# ET6801 register map
Vendor: ETMCU Inc.; File version: v0.0.1
CPU: CM7 r2p1, little endian, MPU, FPU, I-cache, D-cache, ITCM, DTCM, 4 interrupt priority bits
Registers are 32-bit, read-write, reset 0x0 unless marked. A register's access mark holds for its fields unless they carry their own. Offsets are from the block's base; [hi:lo] are bit positions.

## SRAMCTL0 — Provide an overview of the purpose and functionality of the peripheral: axi2sram
Base 0x40608000
Same registers: SRAMCTL1 0x40609000
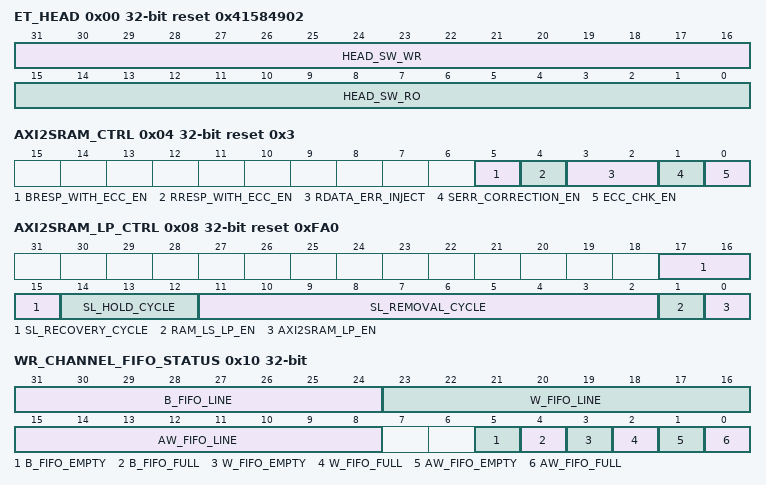
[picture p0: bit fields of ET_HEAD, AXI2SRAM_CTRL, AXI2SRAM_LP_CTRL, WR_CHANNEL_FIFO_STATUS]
0x00 ET_HEAD reset 0x41584902
  [31:16] HEAD_SW_WR — 软件测试读写寄存器，硬件无访问
  [15:0] HEAD_SW_RO ro — 软件只读上报寄存器，硬件无访问
0x04 AXI2SRAM_CTRL reset 0x3
  [5] BRESP_WITH_ECC_EN — AXI2SRAM bresp ecc使能
  [4] RRESP_WITH_ECC_EN — AXI2SRAM rresp ecc使能
  [3:2] RDATA_ERR_INJECT — AXI2SRAM ECC注错使能
  [1] SERR_CORRECTION_EN — AXI2SRAM ECC单bit错误纠错使能
  [0] ECC_CHK_EN — AXI2SRAM ECC使能
0x08 AXI2SRAM_LP_CTRL reset 0xFA0
  [17:15] SL_RECOVERY_CYCLE — MEM_RAM Light-sleep recovery时间配置，默认为0
  [14:12] SL_HOLD_CYCLE — MEM_RAM Light-sleep hold时间配置，默认为0
  [11:2] SL_REMOVAL_CYCLE — MEM_RAM Light-sleep removal时间配置，默认为1000
  [1] RAM_LS_LP_EN — MEM_RAM Light-sleep低功耗使能
  [0] AXI2SRAM_LP_EN — AXI2SRAM 内部数据流低功耗使能
0x0C R_FIFO_AFULL_THRESHOLD reset 0x3
  [1:0] R_FIFO_AFULL_THRESHOLD — R Channel FIFO 将满门限，当fifo_line>= r_fifo_afull_threshold，则置起fifo_afull信号，反压路径中的数据。 推荐默认配置，同时硬件防呆，避免错误配置 ： 如果超过`FIFO_DEPTH - `PIPELINE，则固定到该上限值。 如果小于`PIPELINE + 'hF，则固定到该下限值。
0x10 WR_CHANNEL_FIFO_STATUS ro
  [31:24] B_FIFO_LINE — B FIFO水线
  [23:16] W_FIFO_LINE — W FIFO水线
  [15:8] AW_FIFO_LINE — AW FIFO水线
  [5] B_FIFO_EMPTY — B FIFO空
  [4] B_FIFO_FULL — B FIFO满
  [3] W_FIFO_EMPTY — W FIFO空
  [2] W_FIFO_FULL — W FIFO 满
  [1] AW_FIFO_EMPTY — AW FIFO空
  [0] AW_FIFO_FULL — AW FIFO满
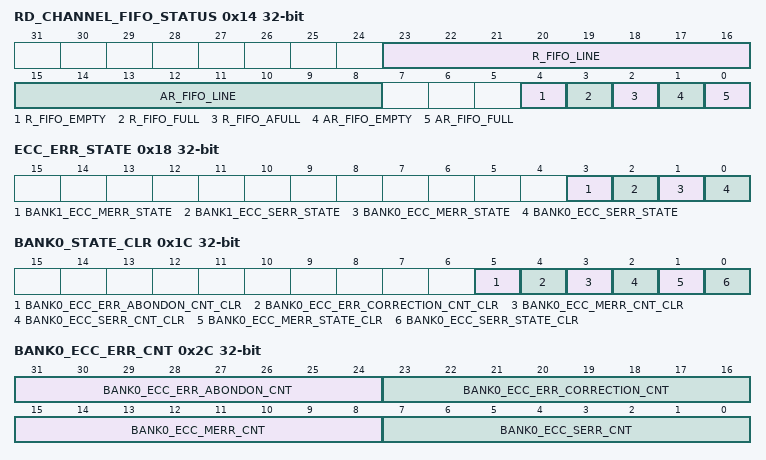
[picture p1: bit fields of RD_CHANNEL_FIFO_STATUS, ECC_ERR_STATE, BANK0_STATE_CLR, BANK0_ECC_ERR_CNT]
0x14 RD_CHANNEL_FIFO_STATUS ro
  [23:16] R_FIFO_LINE — R FIFO水线
  [15:8] AR_FIFO_LINE — AR FIFO水线
  [4] R_FIFO_EMPTY — R FIFO空
  [3] R_FIFO_FULL — R FIFO满
  [2] R_FIFO_AFULL — R FIFO 将满
  [1] AR_FIFO_EMPTY — AR FIFO空
  [0] AR_FIFO_FULL — AR FIFO满
0x18 ECC_ERR_STATE ro
  [3] BANK1_ECC_MERR_STATE — bank1 ecc 2bit错误状态，发生2bit错误，则上报2bit错误状态，该状态可由bank1_ecc_merr_state_clr清除。
  [2] BANK1_ECC_SERR_STATE — bank1 ecc 1bit错误状态，发生单bit错误，并且错误数量大于等于bank1_ecc_serr_threshold的中断阈值，则上报单bit错误状态，该状态可由bank1_ecc_serr_state_clr清除。
  [1] BANK0_ECC_MERR_STATE — bank0 ecc 2bit错误状态，发生2bit错误，则上报2bit错误状态，该状态可由bank0_ecc_merr_state_clr清除。
  [0] BANK0_ECC_SERR_STATE — bank0 ecc 1bit错误状态 ，发生单bit错误，并且错误数量大于等于bank0_ecc_serr_threshold的中断阈值，则上报单bit错误状态，该状态可由bank0_ecc_serr_state_clr清除。
0x1C BANK0_STATE_CLR
  [5] BANK0_ECC_ERR_ABONDON_CNT_CLR wo — bank0 1bit ECC错误放弃纠错计数清除
  [4] BANK0_ECC_ERR_CORRECTION_CNT_CLR wo — bank0 1bit ECC错误纠错计数清除
  [3] BANK0_ECC_MERR_CNT_CLR wo — bank0 2bit ECC错误数量清除
  [2] BANK0_ECC_SERR_CNT_CLR wo — bank0 1bit ECC错误数量清除
  [1] BANK0_ECC_MERR_STATE_CLR wo — bank0 2bit ECC错误状态清除
  [0] BANK0_ECC_SERR_STATE_CLR wo — bank0 1bit ECC错误状态清除
0x20 BANK0_ECC_SERR_ADDR ro
  [31:0] BANK0_ECC_SERR_ADDR — bank0 ecc 1bit错误地址 31:20 AXI2SRAM_BASE_ADDR-axi2sram的基地址 19 : (20-`AXI2SRAM_MEM_ADDR) bank0响应地址 19-`AXI2SRAM_MEM_ADDR bank0请求的source id，source_id=1表示返回的是AXI的写transaction，source_id=0示返回的是AXI的读ransaction 18-`AXI2SRAM_MEM_ADDR : 0 无含义 比如，当bank0为16KB时，则`AXI2SRAM_MEM_ADDR=11 31:20 AXI2SRAM_BASE_ADDR-axi2sram的基地址 19:9 bank0响应地址 8 bank0请求的source id，source_id=1表示返回的是AXI的写transaction，source_id=0示返回的是AXI的读ransaction 7 : 0 无含义
0x24 BANK0_ECC_MERR_ADDR ro
  [31:0] BANK0_ECC_MERR_ADDR — bank0 ecc 2bit错误地址 31:20 AXI2SRAM_BASE_ADDR-axi2sram的基地址 19 : (20-`AXI2SRAM_MEM_ADDR) bank0响应地址 19-`AXI2SRAM_MEM_ADDR bank0请求的source id，source_id=1表示返回的是AXI的写transaction，source_id=0示返回的是AXI的读ransaction 18-`AXI2SRAM_MEM_ADDR : 0 无含义 比如，当bank0为16KB时，则`AXI2SRAM_MEM_ADDR=11 31:20 AXI2SRAM_BASE_ADDR-axi2sram的基地址 19:9 bank0响应地址 8 bank0请求的source id，source_id=1表示返回的是AXI的写transaction，source_id=0示返回的是AXI的读ransaction 7 : 0 无含义
0x28 BANK0_CORRECTION_CUR_ADDR ro
  [31:0] BANK0_CORRECTION_CUR_ADDR — bank0 ecc 1bit错误纠错地址 31:20 AXI2SRAM_BASE_ADDR-axi2sram的基地址 19 : (20-`AXI2SRAM_MEM_ADDR) bank0单bit纠错地址 19-`AXI2SRAM_MEM_ADDR 单bit纠错请求的source id 18-`AXI2SRAM_MEM_ADDR : 0 无含义 比如，当bank0为16KB时，则`AXI2SRAM_MEM_ADDR=11 31:20 AXI2SRAM_BASE_ADDR-axi2sram的基地址 19:9 bank0单bit纠错地址 8 单bit纠错请求的source id，source_id=1表示返回的是AXI的写transaction，source_id=0示返回的是AXI的读ransaction 7 : 0 无含义
0x2C BANK0_ECC_ERR_CNT ro
  [31:24] BANK0_ECC_ERR_ABONDON_CNT — bank0 ecc 1bit错误放弃纠错数量，当发生单bit ecc错误时，发出纠错请求，但未找到空隙进行回写，发现同一个地址的写操作，则bank0_ecc_err_abondon_cnt计数加1，该计数值可由bank0_ecc_err_abondon_cnt_clr进行清除，最大记录256个错误。
  [23:16] BANK0_ECC_ERR_CORRECTION_CNT — bank0 ecc 1bit错误纠错数量，当发生单bit ecc错误时，发出纠错请求，并找到空隙进行回写，则bank0_ecc_err_correction_cnt计数加1，该计数值可由bank0_ecc_err_correction_cnt_clr进行清除，最大记录256个错误。
  [15:8] BANK0_ECC_MERR_CNT — bank0 ecc 2bit错误数量，每发生一次2bit ecc错误则bank0_ecc_merr_cnt计数加1，该计数值可由bank0_ecc_merr_cnt_clr进行清除，最大记录256个错误。
  [7:0] BANK0_ECC_SERR_CNT — bank0 ecc 1bit错误数量，每发生一次单bit ecc错误则bank0_ecc_serr_cnt计数加1，该计数值可由bank0_ecc_serr_cnt_clr进行清除，最大记录256个错误。
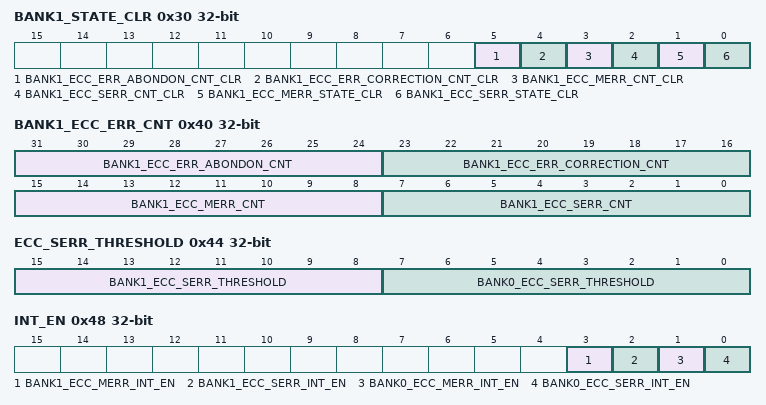
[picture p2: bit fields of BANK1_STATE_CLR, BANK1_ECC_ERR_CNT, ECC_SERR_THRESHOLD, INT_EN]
0x30 BANK1_STATE_CLR
  [5] BANK1_ECC_ERR_ABONDON_CNT_CLR wo — bank1 1bit ECC错误放弃纠错计数清除
  [4] BANK1_ECC_ERR_CORRECTION_CNT_CLR wo — bank1 1bit ECC错误纠错计数清除
  [3] BANK1_ECC_MERR_CNT_CLR wo — bank1 2bit ECC错误状态清除
  [2] BANK1_ECC_SERR_CNT_CLR wo — bank1 1bit ECC错误数量清除
  [1] BANK1_ECC_MERR_STATE_CLR wo — bank1 2bit ECC错误状态清除
  [0] BANK1_ECC_SERR_STATE_CLR wo — bank1 1bit ECC错误状态清除
0x34 BANK1_ECC_SERR_ADDR ro
  [31:0] BANK1_ECC_SERR_ADDR — bank1 1bit ECC错误地址 31:20 AXI2SRAM_BASE_ADDR-axi2sram的基地址 19 : (20-`AXI2SRAM_MEM_ADDR) bank1响应地址 19-`AXI2SRAM_MEM_ADDR bank1请求的source id，source_id=1表示返回的是AXI的写transaction，source_id=0示返回的是AXI的读ransaction 18-`AXI2SRAM_MEM_ADDR : 0 无含义 比如，当bank1为16KB时，则`AXI2SRAM_MEM_ADDR=11 31:20 AXI2SRAM_BASE_ADDR-axi2sram的基地址 19:9 bank1响应地址 8 bank1请求的source id，source_id=1表示返回的是AXI的写transaction，source_id=0示返回的是AXI的读ransaction 7 : 0 无含义
0x38 BANK1_ECC_MERR_ADDR ro
  [31:0] BANK1_ECC_MERR_ADDR — bank1 2bit ECC错误地址 31:20 AXI2SRAM_BASE_ADDR-axi2sram的基地址 19 : (20-`AXI2SRAM_MEM_ADDR) bank1响应地址 19-`AXI2SRAM_MEM_ADDR bank1请求的source id，source_id=1表示返回的是AXI的写transaction，source_id=0示返回的是AXI的读ransaction 18-`AXI2SRAM_MEM_ADDR : 0 无含义 比如，当bank1为16KB时，则`AXI2SRAM_MEM_ADDR=11 31:20 AXI2SRAM_BASE_ADDR-axi2sram的基地址 19:9 bank1响应地址 8 bank1请求的source id，source_id=1表示返回的是AXI的写transaction，source_id=0示返回的是AXI的读ransaction 7 : 0 无含义
0x3C BANK1_CORRECTION_CUR_ADDR ro
  [31:0] BANK1_CORRECTION_CUR_ADDR — bank1 ecc 1bit错误纠错地址 31:20 AXI2SRAM_BASE_ADDR-axi2sram的基地址 19 : (20-`AXI2SRAM_MEM_ADDR) bank1单bit纠错地址 19-`AXI2SRAM_MEM_ADDR 单bit纠错请求的source id，source_id=1表示返回的是AXI的写transaction，source_id=0示返回的是AXI的读ransaction 18-`AXI2SRAM_MEM_ADDR : 0 无含义 比如，当bank1为16KB时，则`AXI2SRAM_MEM_ADDR=11 31:20 AXI2SRAM_BASE_ADDR-axi2sram的基地址 19:9 bank1单bit纠错地址 8 单bit纠错请求的source id，source_id=1表示返回的是AXI的写transaction，source_id=0示返回的是AXI的读ransaction 7 : 0 无含义
0x40 BANK1_ECC_ERR_CNT ro
  [31:24] BANK1_ECC_ERR_ABONDON_CNT — bank1 ecc 1bit错误放弃纠错数量，当发生单bit ecc错误时，发出纠错请求，但未找到空隙进行回写，发现同一个地址的写操作，则bank1_ecc_err_abondon_cnt计数加1，该计数值可由bank1_ecc_err_abondon_cnt_clr进行清除，最大记录256个错误。
  [23:16] BANK1_ECC_ERR_CORRECTION_CNT — bank1 ecc 1bit错误纠错数量，当发生单bit ecc错误时，发出纠错请求，并找到空隙进行回写，则bank1_ecc_err_correction_cnt计数加1，该计数值可由bank1_ecc_err_correction_cnt_clr进行清除，最大记录256个错误。
  [15:8] BANK1_ECC_MERR_CNT — bank1 ecc 2bit错误数量，每发生一次2bit ecc错误则bank1_ecc_merr_cnt计数加1，该计数值可由bank1_ecc_merr_cnt_clr进行清除，最大记录256个错误。
  [7:0] BANK1_ECC_SERR_CNT — bank1 ecc 1bit错误数量，每发生一次单bit ecc错误则bank1_ecc_serr_cnt计数加1，该计数值可由bank1_ecc_serr_cnt_clr进行清除，最大记录256个错误。
0x44 ECC_SERR_THRESHOLD
  [15:8] BANK1_ECC_SERR_THRESHOLD — bank1 ECC serr中断阈值，当单bit错误数量大于等于bank1_ecc_serr_threshold的中断阈值，则上报单bit错误状态
  [7:0] BANK0_ECC_SERR_THRESHOLD — bank0 ECC serr中断阈值，当单bit错误数量大于等于bank0_ecc_serr_threshold的中断阈值，则上报单bit错误状态。
0x48 INT_EN
  [3] BANK1_ECC_MERR_INT_EN — BANK1 2bit ECC错误使能 1'b0:不使能 1'b1:使能
  [2] BANK1_ECC_SERR_INT_EN — BANK1 1bit ECC错误使能 1'b0:不使能 1'b1:使能
  [1] BANK0_ECC_MERR_INT_EN — BANK0 2bit ECC错误使能 1'b0:不使能 1'b1:使能
  [0] BANK0_ECC_SERR_INT_EN — BANK0 1bit ECC错误使能 1'b0:不使能 1'b1:使能
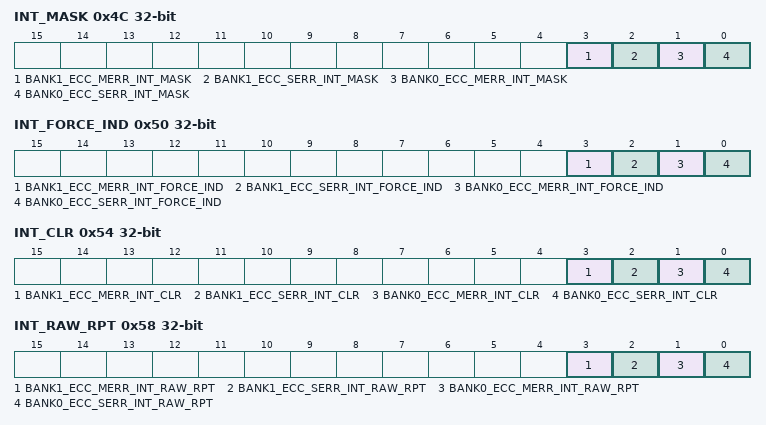
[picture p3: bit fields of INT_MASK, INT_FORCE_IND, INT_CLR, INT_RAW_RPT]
0x4C INT_MASK
  [3] BANK1_ECC_MERR_INT_MASK — BANK1 2bit ECC错误屏蔽使能 1'b0:不屏蔽 1'b1:屏蔽
  [2] BANK1_ECC_SERR_INT_MASK — BANK1 1bit ECC错误屏蔽使能 1'b0:不屏蔽 1'b1:屏蔽
  [1] BANK0_ECC_MERR_INT_MASK — BANK0 2bit ECC错误屏蔽使能 1'b0:不屏蔽 1'b1:屏蔽
  [0] BANK0_ECC_SERR_INT_MASK — BANK0 1bit ECC错误屏蔽使能 1'b0:不屏蔽 1'b1:屏蔽
0x50 INT_FORCE_IND
  [3] BANK1_ECC_MERR_INT_FORCE_IND wo — BANK1 2bit ECC错误强制使能 1'b0:强制中断无效 1'b1:强制中断,硬件自动清零
  [2] BANK1_ECC_SERR_INT_FORCE_IND wo — BANK1 1bit ECC错误强制使能 1'b0:强制中断无效 1'b1:强制中断,硬件自动清零
  [1] BANK0_ECC_MERR_INT_FORCE_IND wo — BANK0 2bit ECC错误强制使能 1'b0:强制中断无效 1'b1:强制中断,硬件自动清零
  [0] BANK0_ECC_SERR_INT_FORCE_IND wo — BANK0 1bit ECC错误强制使能 1'b0:强制中断无效 1'b1:强制中断,硬件自动清零
0x54 INT_CLR
  [3] BANK1_ECC_MERR_INT_CLR wo — BANK1 2bit ECC错误清除 1'b0:清除无效 1'b1:中断清除,硬件自动清零
  [2] BANK1_ECC_SERR_INT_CLR wo — BANK1 1bit ECC错误清除 1'b0:清除无效 1'b1:中断清除,硬件自动清零
  [1] BANK0_ECC_MERR_INT_CLR wo — BANK0 2bit ECC错误清除 1'b0:清除无效 1'b1:中断清除,硬件自动清零
  [0] BANK0_ECC_SERR_INT_CLR wo — BANK0 1bit ECC错误清除 1'b0:清除无效 1'b1:中断清除,硬件自动清零
0x58 INT_RAW_RPT ro
  [3] BANK1_ECC_MERR_INT_RAW_RPT — BANK1 2bit ECC原始中断 1'b0:原始中断无效 1'b1:原始中断有效
  [2] BANK1_ECC_SERR_INT_RAW_RPT — BANK1 1bit ECC原始中断 1'b0:原始中断无效 1'b1:原始中断有效
  [1] BANK0_ECC_MERR_INT_RAW_RPT — BANK0 2bit ECC原始中断 1'b0:原始中断无效 1'b1:原始中断有效
  [0] BANK0_ECC_SERR_INT_RAW_RPT — BANK0 1bit ECC原始中断 1'b0:原始中断无效 1'b1:原始中断有效
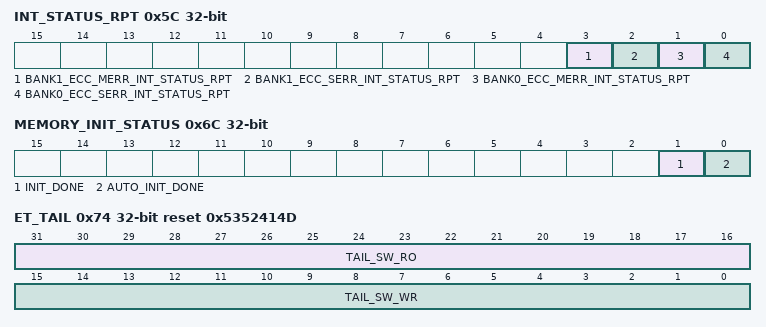
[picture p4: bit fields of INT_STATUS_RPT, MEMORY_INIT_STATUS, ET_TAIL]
0x5C INT_STATUS_RPT ro
  [3] BANK1_ECC_MERR_INT_STATUS_RPT — BANK1 2bit ECC错误 1'b0:中断无效 1'b1:中断有效
  [2] BANK1_ECC_SERR_INT_STATUS_RPT — BANK1 1bit ECC错误 1'b0:中断无效 1'b1:中断有效
  [1] BANK0_ECC_MERR_INT_STATUS_RPT — BANK0 2bit ECC错误 1'b0:中断无效 1'b1:中断有效
  [0] BANK0_ECC_SERR_INT_STATUS_RPT — BANK0 1bit ECC错误 1'b0:中断无效 1'b1:中断有效
0x60 INIT_EN
  [0] INIT_EN wo
0x64 INIT_ADDR_BEGIN
  [31:0] INIT_ADDR_BEGIN — 配置初始化起始地址
0x68 INIT_ADDR_END reset 0xFFFFFFFF
  [31:0] INIT_ADDR_END — 配置初始化结束地址
0x6C MEMORY_INIT_STATUS ro
  [1] INIT_DONE — 配置初始化完成
  [0] AUTO_INIT_DONE — 自动初始化完成
0x70 MASTER_P
  [31:0] APB_MASTER_BITMAP — APB访问保护配置
0x74 ET_TAIL reset 0x5352414D
  [31:16] TAIL_SW_RO ro — 软件只读硬件上报寄存器
  [15:0] TAIL_SW_WR — 软件测试读写寄存器，硬件无访问
